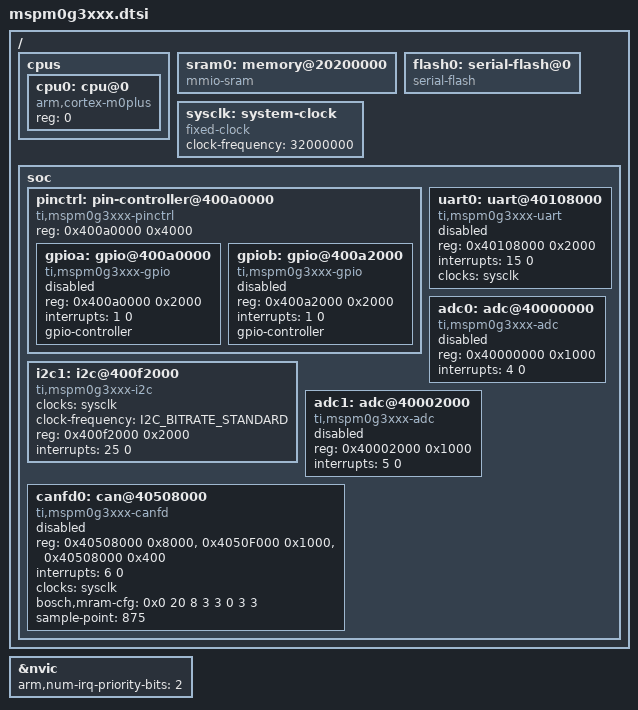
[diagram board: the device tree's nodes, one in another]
/* SPDX-License-Identifier: Apache-2.0 */

#include <arm/armv6-m.dtsi>
#include <zephyr/dt-bindings/gpio/gpio.h>
#include <zephyr/dt-bindings/i2c/i2c.h>
#include <zephyr/dt-bindings/adc/adc.h>
#include <zephyr/dt-bindings/adc/mspm0_adc.h>

/ {

	cpus {
		#address-cells = <1>;
		#size-cells = <0>;

		cpu0: cpu@0 {
			compatible = "arm,cortex-m0plus";
			reg = <0>;
		};
	};

	sram0: memory@20200000 {
		compatible = "mmio-sram";
	};

	flash0: serial-flash@0 {
		compatible = "serial-flash";
	};

	sysclk: system-clock {
		compatible = "fixed-clock";
		clock-frequency = <32000000>;
		#clock-cells = <0>;
	};

	soc {

		pinctrl: pin-controller@400a0000{
			compatible = "ti,mspm0g3xxx-pinctrl";
			#address-cells = <1>;
			#size-cells = <1>;
			reg = <0x400a0000 0x4000>;

			gpioa: gpio@400a0000 {
				compatible = "ti,mspm0g3xxx-gpio";
				reg = <0x400a0000 0x2000>;
				interrupts = <1 0>;
				status = "disabled";
				gpio-controller;
				#gpio-cells = <2>;
			};

			gpiob: gpio@400a2000 {
				compatible = "ti,mspm0g3xxx-gpio";
				reg = <0x400a2000 0x2000>;
				interrupts = <1 0>;
				status = "disabled";
				gpio-controller;
				#gpio-cells = <2>;
			};

		};

		uart0: uart@40108000 {
			compatible = "ti,mspm0g3xxx-uart";
			reg = <0x40108000 0x2000>;
			interrupts = <15 0>;
			clocks = <&sysclk>;
			status = "disabled";
		};

		i2c1: i2c@400f2000 {
			compatible = "ti,mspm0g3xxx-i2c";
			clocks = <&sysclk>;
			clock-frequency = <I2C_BITRATE_STANDARD>;
			#address-cells = <1>;
			#size-cells = <0>;
			reg = <0x400f2000 0x2000>;
			interrupts = <25 0>;
			status = "okay";
		};

		adc0: adc@40000000 {
			compatible = "ti,mspm0g3xxx-adc";
			reg = <0x40000000 0x1000>;
			interrupts = <4 0>;
			status = "disabled";
			#io-channel-cells = <1>;
		};

		adc1: adc@40002000 {
			compatible = "ti,mspm0g3xxx-adc";
			reg = <0x40002000 0x1000>;
			interrupts = <5 0>;
			status = "disabled";
			#io-channel-cells = <1>;
		};

		canfd0: can@40508000 {
			compatible = "ti,mspm0g3xxx-canfd";
			reg =  <0x40508000 0x8000>, <0x4050F000 0x1000>, <0x40508000 0x400>;
			reg-names = "ti_canfd", "m_can", "message_ram";
			interrupts = <6 0>;
			clocks = <&sysclk>;
			bosch,mram-cfg = <0x0 20 8 3 3 0 3 3>;
			/*
			 * # 20 11-bit filter elements = 20x4  = 80B
			 * # 8  29-bit filter elements =  8x8  = 64B
			 * # 3 RX FIFO0 elements =        3x72 = 216B
			 * # 3 RX FIFO1 elements =        3x72 = 216B
			 * # 0 RX buffer elemets =        0x72 = 0B
			 * # 3 TX FIFO elements =         3x8  = 24B
			 * # 3 TX Buffer elements =       3x72 = 216B
			 * # Total RAM                         = 816B
			 */
			status = "disabled";
			sample-point = <875>;
		};
	};
};

&nvic {
	arm,num-irq-priority-bits = <2>;
};
